# PIC32CK1012GC00048 device description
Architecture: CORTEX-M33; Family: PIC32CK; Series: PIC32CKGC00
Registers are 32-bit, read-write, reset 0x0 unless marked. A register's access mark holds for its fields unless they carry their own. Offsets are from the block's base; [hi:lo] are bit positions; {n}, {i} and the like mark numbered series; 'fields as' and 'values as' point back to an identical list.

## Event users
0 FREQM_START, 1 RTC_TAMPER, {n+2} PORT_EV_{n} (n=0..3), {n+6} DMA0_CHSTRT_{n} (n=0..7), {n+14} DMA0_CHAUX_{n} (n=0..7), {n+22} DMA1_CHSTRT_{n} (n=0..3), {n+26} DMA1_CHAUX_{n} (n=0..3), {8n+30} TCC{n}_EV_0 (n=0..4), {8n+31} TCC{n}_EV_1 (n=0..4), {8n+32} TCC{n}_MC_0 (n=0..4), {8n+33} TCC{n}_MC_1 (n=0..4), {8n+34} TCC{n}_MC_2 (n=0..3), {8n+35} TCC{n}_MC_3 (n=0..3), {8n+36} TCC{n}_MC_4 (n=0..3), {8n+37} TCC{n}_MC_5 (n=0..3), 66 TCC5_EV_0, 67 TCC5_EV_1, 68 TCC5_MC_0, 69 TCC5_MC_1, 70 FAKE_TCC6_EV_0, 71 FAKE_TCC6_EV_1, 72 FAKE_TCC6_MC_0, 73 FAKE_TCC6_MC_1, 74 FAKE_TCC7_EV_0, 75 FAKE_TCC7_EV_1, 76 FAKE_TCC7_MC_0, 77 FAKE_TCC7_MC_1, {n+78} ADC_TRIGGERS_{n} (n=0..10), 89 AC_SOC_0, 90 AC_SOC_1, {n+93} CCL_LUTIN_{n} (n=0..3), {n+97} PDEC_EVU_{n} (n=0..2)

## Properties
SIGNATURES: DSU_DID=0x19586053

## Pinouts (pin number, pad)
P48: 1 PA00, 2 PA01, 3 PA02, 4 PA03, 5 RESET_N, 6 VDDIO, 7 GND, 8 PA06, 9 PA07, 10 PA09, 11 ATEST, 12 PA11, 13 PA12, 14 PB00, 15 VREFH, 16 VSSA, 17 PB02, 18 PB03, 19 VDDA, 20 PB04, 21 PB05, 22 PB06, 23 VDDIO, 24 VDDREG, 25 GND, 26 PC00, 27 PC01, 28 PC02, 29 PC03, 30 VDDIO, 31 GND, 32 PC05, 33 PC06, 34 PC07, 35 VDDREG, 36 PC10, 37 PC11, 38 VSSIO, 39 VDDIO, 40 PD00, 41 PD01, 42 PD02, 43 PD03, 44 PD04, 45 PD06, 46 PD07, 47 VDDIOB, 48 GND

## CCL — Configurable Custom Logic
Instances: CCL 0x4501A000
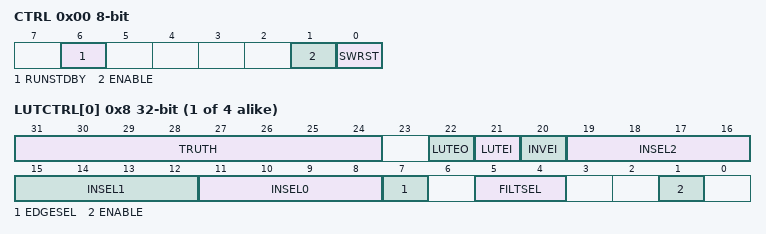
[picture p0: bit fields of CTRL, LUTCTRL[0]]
0x00 CTRL 8-bit — Control
  [6] RUNSTDBY — Run in Standby
    0=DISABLE (Generic clock is not required in standby sleep mode); 1=ENABLE (Generic clock is required in standby sleep mode)
  [1] ENABLE
    0=DISABLE (The peripheral is disabled); 1=ENABLE (The peripheral is enabled)
  [0] SWRST — Software Reset
    0=DISABLE (The peripheral is not reset); 1=ENABLE (The peripheral is reset)
{0x4+i} SEQCTRL[{i}] (i=0..1) 8-bit — SEQ Control x
  [3:0] SEQSEL — Sequential Selection
    0=DISABLE (Sequential logic is disabled); 1=DFF (D flip flop); 2=JK (JK flip flop); 3=LATCH (D latch); 4=RS (RS latch)
{0x8+4i} LUTCTRL[{i}] (i=0..3) — LUT Control x
  [31:24] TRUTH — Truth Value
  [22] LUTEO — LUT Event Output Enable
    0=DISABLE (LUT event output is disabled); 1=ENABLE (LUT event output is enabled)
  [21] LUTEI — LUT Event Input Enable
    0=DISABLE (LUT incoming event is disabled); 1=ENABLE (LUT incoming event is enabled)
  [20] INVEI — Inverted Event Input Enable
    0=NORMAL (Incoming event is not inverted); 1=INVERTED (Incoming event is inverted)
  [19:16] INSEL2 — Input Selection 2
    0=MASK (Masked input); 1=FEEDBACK (Feedback input source); 2=LINK (Linked LUT input source); 3=EVENT (Event input source); 4=IO (I/O pin input source); 5=AC (AC input source); 6=TC (TC input source); 7=ALTTC (Alternate TC input source); 8=TCC (TCC input source); 9=SERCOM (SERCOM input source); 11=ASYNCEVENT (Asynchronous event input source)
  [15:12] INSEL1 — Input Selection 1
    values as INSEL2
  [11:8] INSEL0 — Input Selection 0
    values as INSEL2
  [7] EDGESEL — Edge Selection
    0=DISABLE (Edge detector is disabled); 1=ENABLE (Edge detector is enabled)
  [5:4] FILTSEL — Filter Selection
    0=DISABLE (Filter disabled); 1=SYNCH (Synchronizer enabled); 2=FILTER (Filter enabled)
  [1] ENABLE — LUT Enable
    0=DISABLE (LUT block is disabled); 1=ENABLE (LUT block is enabled)

## CMCC — Cortex M Cache Controller
Instances: CMCC 0x44808000
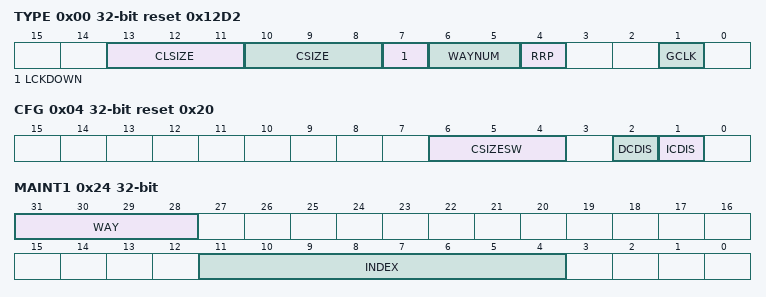
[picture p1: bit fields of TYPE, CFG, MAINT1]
0x00 TYPE ro reset 0x12D2 — Cache Type Register
  [13:11] CLSIZE — Cache Line Size
    0=CLSIZE_4B (Cache Line Size is 4 bytes); 1=CLSIZE_8B (Cache Line Size is 8 bytes); 2=CLSIZE_16B (Cache Line Size is 16 bytes); 3=CLSIZE_32B (Cache Line Size is 32 bytes); 4=CLSIZE_64B (Cache Line Size is 64 bytes); 5=CLSIZE_128B (Cache Line Size is 128 bytes)
  [10:8] CSIZE — Cache Size
    0=CSIZE_1KB (Cache Size is 1 KB); 1=CSIZE_2KB (Cache Size is 2 KB); 2=CSIZE_4KB (Cache Size is 4 KB); 3=CSIZE_8KB (Cache Size is 8 KB); 4=CSIZE_16KB (Cache Size is 16 KB); 5=CSIZE_32KB (Cache Size is 32 KB); 6=CSIZE_64KB (Cache Size is 64 KB)
  [7] LCKDOWN — Lock Down supported
  [6:5] WAYNUM — Number of Way
    0=DMAPPED (Direct Mapped Cache); 1=ARCH2WAY (2-WAY set associative); 2=ARCH4WAY (4-WAY set associative)
  [4] RRP — Round Robin Policy supported
  [1] GCLK — dynamic Clock Gating supported
0x04 CFG reset 0x20 — Cache Configuration Register
  [6:4] CSIZESW — Cache size configured by software
    0=CONF_CSIZE_1KB (The Cache Size is configured to 1KB); 1=CONF_CSIZE_2KB (The Cache Size is configured to 2KB); 2=CONF_CSIZE_4KB (The Cache Size is configured to 4KB); 3=CONF_CSIZE_8KB (The Cache Size is configured to 8KB); 4=CONF_CSIZE_16KB (The Cache Size is configured to 16KB); 5=CONF_CSIZE_32KB (The Cache Size is configured to 32KB); 6=CONF_CSIZE_64KB (The Cache Size is configured to 64KB)
  [2] DCDIS — Data Cache Disable
  [1] ICDIS — Instruction Cache Disable
0x08 CTRL wo — Cache Control Register
  [0] CEN — Cache Controller Enable
0x0C SR ro — Cache Status Register
  [0] CSTS — Cache Controller Status
0x10 LCKWAY — Cache Lock per Way Register
  [3:0] LCKWAY — Lockdown way Register
0x20 MAINT0 wo — Cache Maintenance Register 0
  [0] INVALL — Cache Controller invalidate All
0x24 MAINT1 wo — Cache Maintenance Register 1
  [31:28] WAY — Invalidate Way
    {v}=Way {v} is selection for index invalidation (v=0..3)
  [11:4] INDEX — Invalidate Index
0x28 MCFG — Cache Monitor Configuration Register
  [1:0] MODE — Cache Controller Monitor Counter Mode
    0=CYCLE_COUNT (Cycle counter); 1=IHIT_COUNT (Instruction hit counter); 2=DHIT_COUNT (Data hit counter)
0x2C MEN — Cache Monitor Enable Register
  [0] MENABLE — Cache Controller Monitor Enable
0x30 MCTRL wo — Cache Monitor Control Register
  [0] SWRST — Cache Controller Software Reset
0x34 MSR ro — Cache Monitor Status Register
  [31:0] EVENT_CNT — Monitor Event Counter
